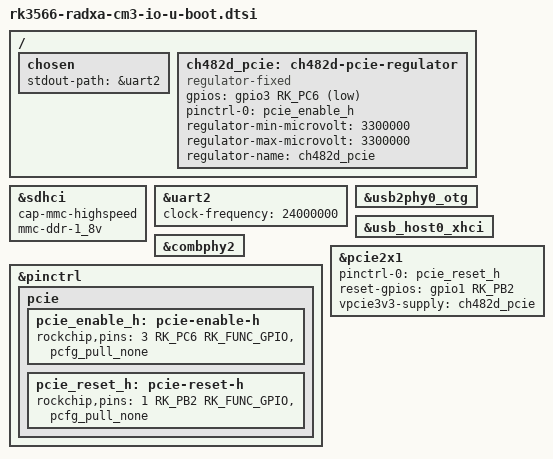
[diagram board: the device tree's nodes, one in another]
// SPDX-License-Identifier: GPL-2.0+
/*
 * (C) Copyright 2021 Rockchip Electronics Co., Ltd
 */

#include "rk356x-u-boot.dtsi"

/ {
	chosen {
		stdout-path = &uart2;
	};

	ch482d_pcie: ch482d-pcie-regulator {
		compatible = "regulator-fixed";
		gpios = <&gpio3 RK_PC6 GPIO_ACTIVE_LOW>;
		pinctrl-names = "default";
		pinctrl-0 = <&pcie_enable_h>;
		regulator-min-microvolt = <3300000>;
		regulator-max-microvolt = <3300000>;
		regulator-name = "ch482d_pcie";
	};
};

&sdhci {
	cap-mmc-highspeed;
	mmc-ddr-1_8v;
};

&uart2 {
	clock-frequency = <24000000>;
	bootph-all;
	status = "okay";
};

&usb2phy0_otg {
	status = "okay";
};

&usb_host0_xhci {
	status = "okay";
};

&combphy2 {
	status = "okay";
};

&pinctrl {
	pcie {
		pcie_enable_h: pcie-enable-h {
			rockchip,pins = <3 RK_PC6 RK_FUNC_GPIO &pcfg_pull_none>;
		};

		pcie_reset_h: pcie-reset-h {
			rockchip,pins = <1 RK_PB2 RK_FUNC_GPIO &pcfg_pull_none>;
		};
	};
};

&pcie2x1 {
	pinctrl-names = "default";
	pinctrl-0 = <&pcie_reset_h>;
	reset-gpios = <&gpio1 RK_PB2 GPIO_ACTIVE_HIGH>;
	vpcie3v3-supply = <&ch482d_pcie>;
	status = "okay";
};
